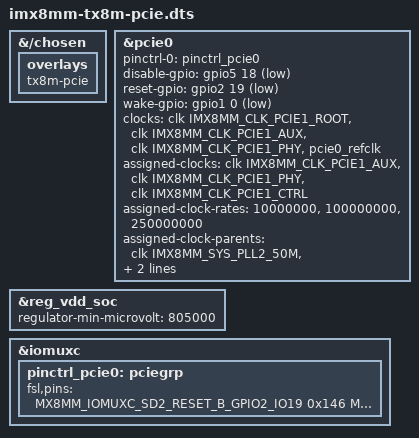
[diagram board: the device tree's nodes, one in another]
// SPDX-License-Identifier: (GPL-2.0 OR MIT)
/*
 * Copyright 2022 Lothar Waßmann <LW@KARO-electronics.de>
 *
 */

/dts-v1/;

/plugin/;

#include <dt-bindings/clock/imx8mm-clock.h>
#include <dt-bindings/gpio/gpio.h>
#include "imx8mm-pinfunc.h"
#include "overlays/imx8m-karo-pcie.dtsi"

&{/chosen} {
	overlays {
		tx8m-pcie;
	};
};

&pcie0 {
	pinctrl-names = "default";
	pinctrl-0 = <&pinctrl_pcie0>;
	disable-gpio = <&gpio5 18 GPIO_ACTIVE_LOW>;
	reset-gpio = <&gpio2 19 GPIO_ACTIVE_LOW>;
	wake-gpio = <&gpio1 0 GPIO_ACTIVE_LOW>;
	clocks = <&clk IMX8MM_CLK_PCIE1_ROOT>,
		 <&clk IMX8MM_CLK_PCIE1_AUX>,
		 <&clk IMX8MM_CLK_PCIE1_PHY>,
		 <&pcie0_refclk>;
	clock-names = "pcie", "pcie_aux", "pcie_phy", "pcie_bus";
	assigned-clocks = <&clk IMX8MM_CLK_PCIE1_AUX>,
			  <&clk IMX8MM_CLK_PCIE1_PHY>,
			  <&clk IMX8MM_CLK_PCIE1_CTRL>;
	assigned-clock-rates = <10000000>, <100000000>, <250000000>;
	assigned-clock-parents = <&clk IMX8MM_SYS_PLL2_50M>,
				 <&clk IMX8MM_SYS_PLL2_100M>,
				 <&clk IMX8MM_SYS_PLL2_250M>;
};

&reg_vdd_soc {
	/* PCIe requires a minimum vdd soc voltage of 0.805V */
	regulator-min-microvolt = <805000>;
};

&iomuxc {
	pinctrl_pcie0: pciegrp {
		fsl,pins = <
			MX8MM_IOMUXC_SD2_RESET_B_GPIO2_IO19	0x146
			MX8MM_IOMUXC_GPIO1_IO00_GPIO1_IO0	0x146
			MX8MM_IOMUXC_I2C3_SCL_GPIO5_IO18	0x146
		>;
	};
};
